VERSION ""

NS_ :

BS_:

BU_:

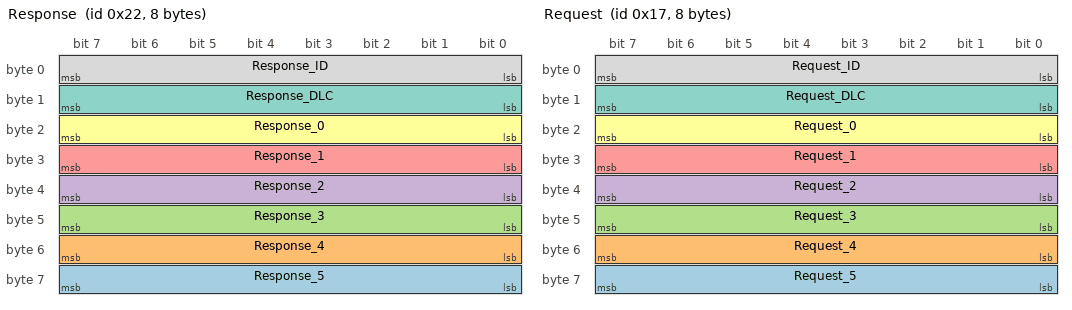
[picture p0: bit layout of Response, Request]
BO_ 34 Response: 8 Vector__XXX
 SG_ Response_5 : 56|8@1- (1,0) [0|0] "" Vector__XXX
 SG_ Response_4 : 48|8@1- (1,0) [0|0] "" Vector__XXX
 SG_ Response_3 : 40|8@1- (1,0) [0|0] "" Vector__XXX
 SG_ Response_2 : 32|8@1- (1,0) [0|0] "" Vector__XXX
 SG_ Response_1 : 24|8@1- (1,0) [0|0] "" Vector__XXX
 SG_ Response_0 : 16|8@1- (1,0) [0|0] "" Vector__XXX
 SG_ Response_DLC : 8|8@1- (1,0) [0|0] "" Vector__XXX
 SG_ Response_ID : 0|8@1- (1,0) [0|0] "" Vector__XXX

BO_ 23 Request: 8 Vector__XXX
 SG_ Request_5 : 56|8@1- (1,0) [0|0] "" Vector__XXX
 SG_ Request_4 : 48|8@1- (1,0) [0|0] "" Vector__XXX
 SG_ Request_3 : 40|8@1- (1,0) [0|0] "" Vector__XXX
 SG_ Request_2 : 32|8@1- (1,0) [0|0] "" Vector__XXX
 SG_ Request_1 : 24|8@1- (1,0) [0|0] "" Vector__XXX
 SG_ Request_0 : 16|8@1- (1,0) [0|0] "" Vector__XXX
 SG_ Request_DLC : 8|8@1- (1,0) [0|0] "" Vector__XXX
 SG_ Request_ID : 0|8@1- (1,0) [0|0] "" Vector__XXX
